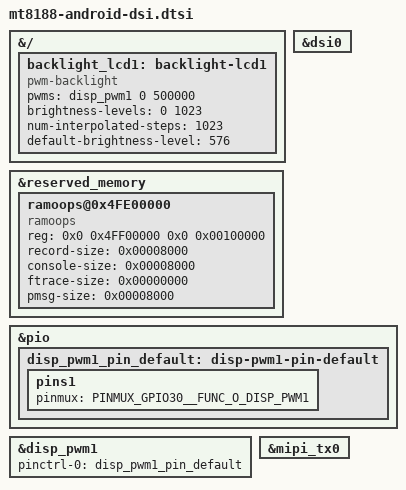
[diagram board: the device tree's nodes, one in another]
// SPDX-License-Identifier: GPL-2.0
/*
 * Copyright (c) 2025 BayLibre, SAS.
 * Author: Julien Masson <jmasson@baylibre.com>
 */

#include <dt-bindings/gpio/gpio.h>
#include <dt-bindings/pinctrl/mediatek,mt8188-pinfunc.h>
#include "dt-bindings/interrupt-controller/irq.h"

&{/} {
	backlight_lcd1: backlight-lcd1 {
		compatible = "pwm-backlight";
		pwms = <&disp_pwm1 0 500000>;
		brightness-levels = <0 1023>;
		num-interpolated-steps = <1023>;
		default-brightness-level = <576>;
	};
};

&dsi0 {
	status = "okay";
};

&reserved_memory {
	#address-cells = <2>;
	#size-cells = <2>;
	ramoops@0x4FE00000 {
		compatible = "ramoops";
		reg = <0x0 0x4FF00000 0x0 0x00100000>;
		record-size = <0x00008000>;
		console-size = <0x00008000>;
		ftrace-size = <0x00000000>;
		pmsg-size = <0x00008000>;
	};
};

&pio {
	disp_pwm1_pin_default: disp-pwm1-pin-default {
		pins1 {
			pinmux = <PINMUX_GPIO30__FUNC_O_DISP_PWM1>;
		};
	};
};

&disp_pwm1 {
	pinctrl-names = "default";
	pinctrl-0 = <&disp_pwm1_pin_default>;
	status = "okay";
};

&mipi_tx0 {
	status = "okay";
};
